VERSION ""

NS_ :

BS_:

BU_: Board Host

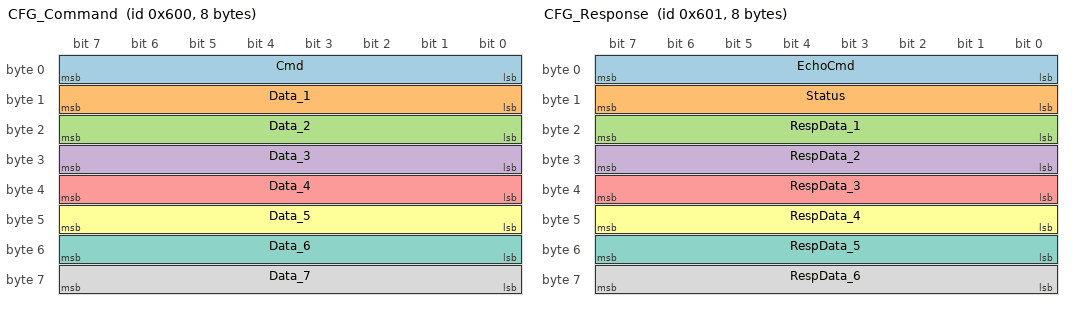
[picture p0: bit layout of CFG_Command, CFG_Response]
BO_ 1536 CFG_Command: 8 Host
 SG_ Cmd : 0|8@1+ (1,0) [0|33] "" Board
 SG_ Data_1 : 8|8@1+ (1,0) [0|255] "" Board
 SG_ Data_2 : 16|8@1+ (1,0) [0|255] "" Board
 SG_ Data_3 : 24|8@1+ (1,0) [0|255] "" Board
 SG_ Data_4 : 32|8@1+ (1,0) [0|255] "" Board
 SG_ Data_5 : 40|8@1+ (1,0) [0|255] "" Board
 SG_ Data_6 : 48|8@1+ (1,0) [0|255] "" Board
 SG_ Data_7 : 56|8@1+ (1,0) [0|255] "" Board

BO_ 1537 CFG_Response: 8 Board
 SG_ EchoCmd : 0|8@1+ (1,0) [0|33] "" Host
 SG_ Status : 8|8@1+ (1,0) [0|5] "" Host
 SG_ RespData_1 : 16|8@1+ (1,0) [0|255] "" Host
 SG_ RespData_2 : 24|8@1+ (1,0) [0|255] "" Host
 SG_ RespData_3 : 32|8@1+ (1,0) [0|255] "" Host
 SG_ RespData_4 : 40|8@1+ (1,0) [0|255] "" Host
 SG_ RespData_5 : 48|8@1+ (1,0) [0|255] "" Host
 SG_ RespData_6 : 56|8@1+ (1,0) [0|255] "" Host

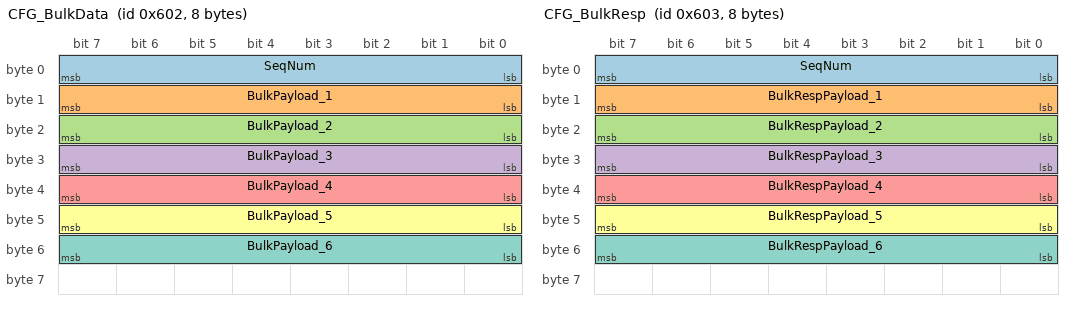
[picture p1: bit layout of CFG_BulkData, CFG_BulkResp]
BO_ 1538 CFG_BulkData: 8 Host
 SG_ SeqNum : 0|8@1+ (1,0) [0|255] "" Board
 SG_ BulkPayload_1 : 8|8@1+ (1,0) [0|255] "" Board
 SG_ BulkPayload_2 : 16|8@1+ (1,0) [0|255] "" Board
 SG_ BulkPayload_3 : 24|8@1+ (1,0) [0|255] "" Board
 SG_ BulkPayload_4 : 32|8@1+ (1,0) [0|255] "" Board
 SG_ BulkPayload_5 : 40|8@1+ (1,0) [0|255] "" Board
 SG_ BulkPayload_6 : 48|8@1+ (1,0) [0|255] "" Board

BO_ 1539 CFG_BulkResp: 8 Board
 SG_ SeqNum : 0|8@1+ (1,0) [0|255] "" Host
 SG_ BulkRespPayload_1 : 8|8@1+ (1,0) [0|255] "" Host
 SG_ BulkRespPayload_2 : 16|8@1+ (1,0) [0|255] "" Host
 SG_ BulkRespPayload_3 : 24|8@1+ (1,0) [0|255] "" Host
 SG_ BulkRespPayload_4 : 32|8@1+ (1,0) [0|255] "" Host
 SG_ BulkRespPayload_5 : 40|8@1+ (1,0) [0|255] "" Host
 SG_ BulkRespPayload_6 : 48|8@1+ (1,0) [0|255] "" Host

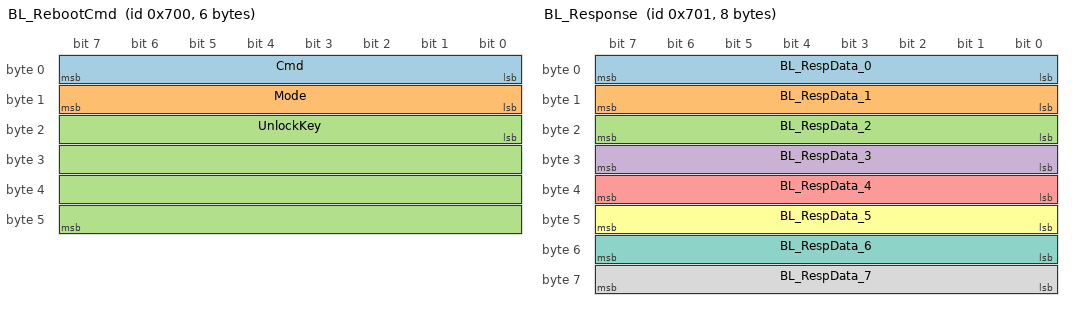
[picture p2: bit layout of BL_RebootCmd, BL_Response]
BO_ 1792 BL_RebootCmd: 6 Host
 SG_ Cmd : 0|8@1+ (1,0) [0|255] "" Board
 SG_ Mode : 8|8@1+ (1,0) [0|255] "" Board
 SG_ UnlockKey : 16|32@1+ (1,0) [0|0] "" Board

BO_ 1793 BL_Response: 8 Board
 SG_ BL_RespData_0 : 0|8@1+ (1,0) [0|255] "" Host
 SG_ BL_RespData_1 : 8|8@1+ (1,0) [0|255] "" Host
 SG_ BL_RespData_2 : 16|8@1+ (1,0) [0|255] "" Host
 SG_ BL_RespData_3 : 24|8@1+ (1,0) [0|255] "" Host
 SG_ BL_RespData_4 : 32|8@1+ (1,0) [0|255] "" Host
 SG_ BL_RespData_5 : 40|8@1+ (1,0) [0|255] "" Host
 SG_ BL_RespData_6 : 48|8@1+ (1,0) [0|255] "" Host
 SG_ BL_RespData_7 : 56|8@1+ (1,0) [0|255] "" Host

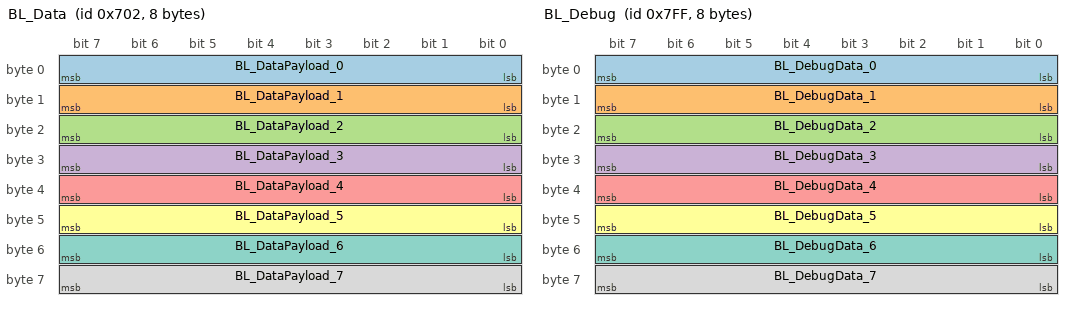
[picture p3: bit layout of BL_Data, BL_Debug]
BO_ 1794 BL_Data: 8 Host
 SG_ BL_DataPayload_0 : 0|8@1+ (1,0) [0|255] "" Board
 SG_ BL_DataPayload_1 : 8|8@1+ (1,0) [0|255] "" Board
 SG_ BL_DataPayload_2 : 16|8@1+ (1,0) [0|255] "" Board
 SG_ BL_DataPayload_3 : 24|8@1+ (1,0) [0|255] "" Board
 SG_ BL_DataPayload_4 : 32|8@1+ (1,0) [0|255] "" Board
 SG_ BL_DataPayload_5 : 40|8@1+ (1,0) [0|255] "" Board
 SG_ BL_DataPayload_6 : 48|8@1+ (1,0) [0|255] "" Board
 SG_ BL_DataPayload_7 : 56|8@1+ (1,0) [0|255] "" Board

BO_ 2047 BL_Debug: 8 Board
 SG_ BL_DebugData_0 : 0|8@1+ (1,0) [0|255] "" Host
 SG_ BL_DebugData_1 : 8|8@1+ (1,0) [0|255] "" Host
 SG_ BL_DebugData_2 : 16|8@1+ (1,0) [0|255] "" Host
 SG_ BL_DebugData_3 : 24|8@1+ (1,0) [0|255] "" Host
 SG_ BL_DebugData_4 : 32|8@1+ (1,0) [0|255] "" Host
 SG_ BL_DebugData_5 : 40|8@1+ (1,0) [0|255] "" Host
 SG_ BL_DebugData_6 : 48|8@1+ (1,0) [0|255] "" Host
 SG_ BL_DebugData_7 : 56|8@1+ (1,0) [0|255] "" Host

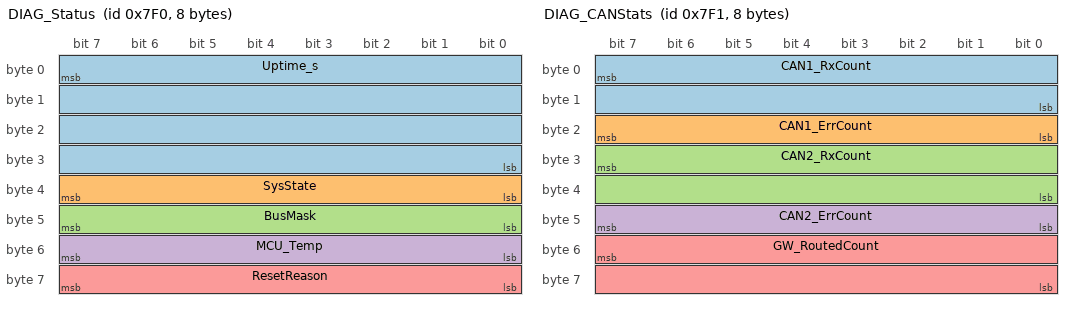
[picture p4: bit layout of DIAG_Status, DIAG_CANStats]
BO_ 2032 DIAG_Status: 8 Board
 SG_ Uptime_s : 7|32@0+ (1,0) [0|0] "s" Host
 SG_ SysState : 32|8@1+ (1,0) [0|3] "" Host
 SG_ BusMask : 40|8@1+ (1,0) [0|63] "" Host
 SG_ MCU_Temp : 48|8@1- (1,0) [-40|125] "degC" Host
 SG_ ResetReason : 56|8@1+ (1,0) [0|3] "" Host

BO_ 2033 DIAG_CANStats: 8 Board
 SG_ CAN1_RxCount : 7|16@0+ (1,0) [0|65535] "" Host
 SG_ CAN1_ErrCount : 16|8@1+ (1,0) [0|255] "" Host
 SG_ CAN2_RxCount : 31|16@0+ (1,0) [0|65535] "" Host
 SG_ CAN2_ErrCount : 40|8@1+ (1,0) [0|255] "" Host
 SG_ GW_RoutedCount : 55|16@0+ (1,0) [0|65535] "" Host

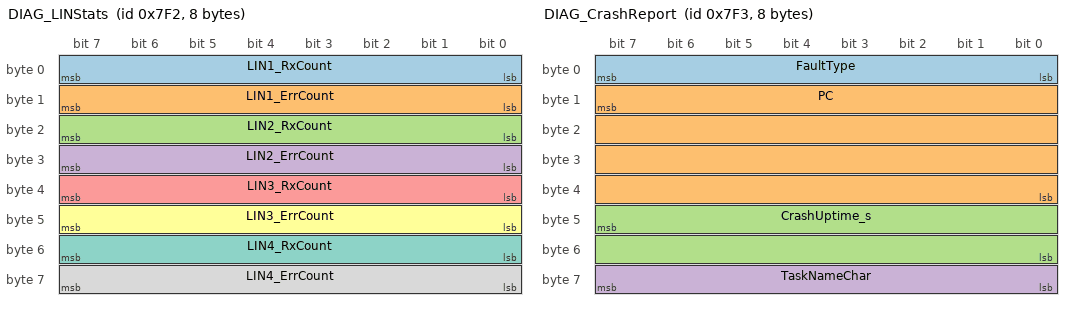
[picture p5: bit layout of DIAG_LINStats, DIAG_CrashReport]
BO_ 2034 DIAG_LINStats: 8 Board
 SG_ LIN1_RxCount : 0|8@1+ (1,0) [0|255] "" Host
 SG_ LIN1_ErrCount : 8|8@1+ (1,0) [0|255] "" Host
 SG_ LIN2_RxCount : 16|8@1+ (1,0) [0|255] "" Host
 SG_ LIN2_ErrCount : 24|8@1+ (1,0) [0|255] "" Host
 SG_ LIN3_RxCount : 32|8@1+ (1,0) [0|255] "" Host
 SG_ LIN3_ErrCount : 40|8@1+ (1,0) [0|255] "" Host
 SG_ LIN4_RxCount : 48|8@1+ (1,0) [0|255] "" Host
 SG_ LIN4_ErrCount : 56|8@1+ (1,0) [0|255] "" Host

BO_ 2035 DIAG_CrashReport: 8 Board
 SG_ FaultType : 0|8@1+ (1,0) [0|5] "" Host
 SG_ PC : 15|32@0+ (1,0) [0|0] "" Host
 SG_ CrashUptime_s : 47|16@0+ (1,0) [0|65535] "s" Host
 SG_ TaskNameChar : 56|8@1+ (1,0) [0|255] "" Host

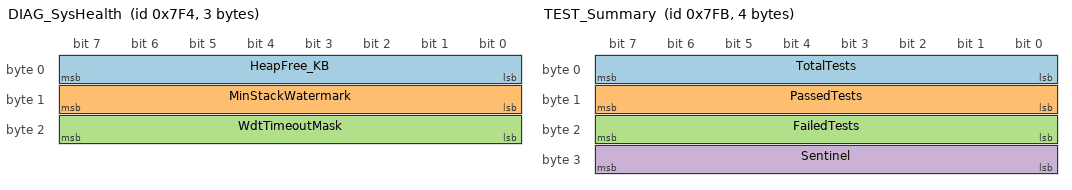
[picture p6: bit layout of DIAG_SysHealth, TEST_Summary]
BO_ 2036 DIAG_SysHealth: 3 Board
 SG_ HeapFree_KB : 0|8@1+ (1,0) [0|255] "KB" Host
 SG_ MinStackWatermark : 8|8@1+ (1,0) [0|255] "words" Host
 SG_ WdtTimeoutMask : 16|8@1+ (1,0) [0|63] "" Host

BO_ 2042 TEST_Result: 8 Board
 SG_ TestID : 0|8@1+ (1,0) [0|255] "" Host
 SG_ Result : 8|8@1+ (1,0) [0|2] "" Host

BO_ 2043 TEST_Summary: 4 Board
 SG_ TotalTests : 0|8@1+ (1,0) [0|255] "" Host
 SG_ PassedTests : 8|8@1+ (1,0) [0|255] "" Host
 SG_ FailedTests : 16|8@1+ (1,0) [0|255] "" Host
 SG_ Sentinel : 24|8@1+ (1,0) [0|255] "" Host

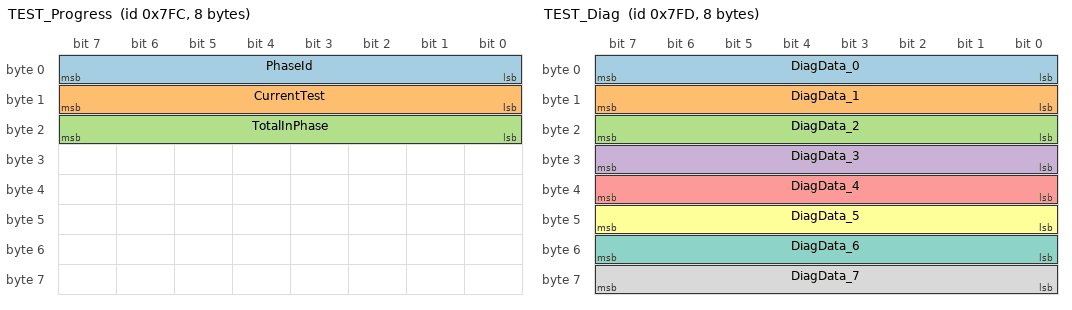
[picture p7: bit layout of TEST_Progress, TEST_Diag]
BO_ 2044 TEST_Progress: 8 Board
 SG_ PhaseId : 0|8@1+ (1,0) [0|255] "" Host
 SG_ CurrentTest : 8|8@1+ (1,0) [0|255] "" Host
 SG_ TotalInPhase : 16|8@1+ (1,0) [0|255] "" Host

BO_ 2045 TEST_Diag: 8 Board
 SG_ DiagData_0 : 0|8@1+ (1,0) [0|255] "" Host
 SG_ DiagData_1 : 8|8@1+ (1,0) [0|255] "" Host
 SG_ DiagData_2 : 16|8@1+ (1,0) [0|255] "" Host
 SG_ DiagData_3 : 24|8@1+ (1,0) [0|255] "" Host
 SG_ DiagData_4 : 32|8@1+ (1,0) [0|255] "" Host
 SG_ DiagData_5 : 40|8@1+ (1,0) [0|255] "" Host
 SG_ DiagData_6 : 48|8@1+ (1,0) [0|255] "" Host
 SG_ DiagData_7 : 56|8@1+ (1,0) [0|255] "" Host

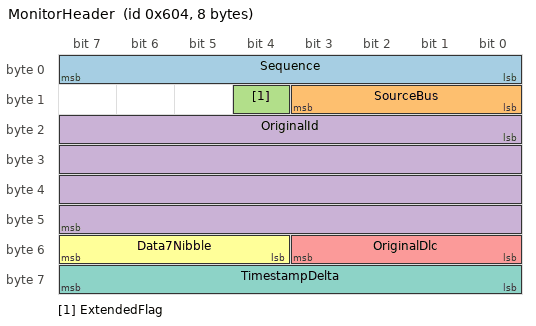
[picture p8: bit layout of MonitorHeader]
BO_ 1540 MonitorHeader: 8 Gateway
 SG_ Sequence : 0|8@1+ (1,0) [0|255] "" Tool
 SG_ SourceBus : 8|4@1+ (1,0) [0|5] "" Tool
 SG_ ExtendedFlag : 12|1@1+ (1,0) [0|1] "" Tool
 SG_ OriginalId : 16|32@1+ (1,0) [0|536870911] "" Tool
 SG_ OriginalDlc : 48|4@1+ (1,0) [0|8] "" Tool
 SG_ Data7Nibble : 52|4@1+ (1,0) [0|15] "" Tool
 SG_ TimestampDelta : 56|8@1+ (1,0) [0|255] "ms" Tool

BO_ 1541 MonitorData: 8 Gateway
 SG_ Sequence : 0|8@1+ (1,0) [0|255] "" Tool
 SG_ Payload : 8|56@1+ (1,0) [0|0] "" Tool

CM_ BU_ Board "CAN/LIN gateway board (RP2350, FreeRTOS). CAN1 always on, CAN2 switchable.";
CM_ BU_ Host "External host tool (Windows config app or PCAN test script).";

CM_ BO_ 1536 "Config command from host. Byte 0 = command code; remaining bytes are command-specific. See config_protocol.h for full details.\n\nCmd values:\n  0x01 CONNECT - no payload, returns FW version\n  0x02 SAVE - save working config to NVM\n  0x03 DEFAULTS - reset config to factory defaults\n  0x04 REBOOT - MCU software reset\n  0x05 ENTER_BL - bytes 1-4: unlock key 0xB007CAFE (LE)\n  0x06 GET_STATUS - returns NVM write count\n  0x10 READ_PARAM - bytes 1-3: section/param/sub\n  0x11 WRITE_PARAM - bytes 1-3: section/param/sub, bytes 4+: value (LE)\n  0x20 BULK_START - byte 1: section, byte 2: sub, bytes 3-4: size (LE), bytes 5-7: CRC24 (LE, lower 24 bits of CRC32)\n  0x21 BULK_END - finalize bulk transfer\n  0x22 BULK_READ - byte 1: section (0x02=routing, 0x01=LIN), byte 2: sub (LIN channel). Response on 0x601 with size+CRC (no data yet)\n  0x23 BULK_READ_DATA - no payload; triggers data stream on 0x603. Must follow a successful BULK_READ";

CM_ BO_ 1537 "Config response from board. Byte 0 echoes the command; byte 1 = status code; bytes 2+ are command-specific payload.\n\nCONNECT response (DLC=8): bytes 2-4: FW major/minor/patch, bytes 5-6: sizeof(nvm_config_t) LE, byte 7: routing rule count.\nGET_STATUS response (DLC=6): bytes 2-5: NVM write count (LE).\nREAD_PARAM response: bytes 2-4: section/param/sub echo, bytes 5+: value (LE).";

CM_ BO_ 1538 "Bulk data frames during bulk write transfer (host to board). Byte 0 = sequence number (0,1,2,...). Bytes 1-7 = payload (up to 7 bytes per frame). No individual ACK per frame; send BULK_END (0x21) to finalize.";

CM_ BO_ 1539 "Bulk data response frames during bulk read transfer (board to host). Sent after a BULK_READ_DATA (0x23) ACK. Byte 0 = sequence number (0,1,2,...). Bytes 1-7 = payload (up to 7 bytes per frame). Host reads total size and CRC from the preceding BULK_READ (0x22) response.";

CM_ BO_ 1792 "Bootloader reboot trigger handled by application firmware. Cmd must be 0x05 (CMD_RESET), Mode must be 0x01 (RESET_MODE_BOOTLOADER). UnlockKey = 0xB007CAFE (little-endian). Board writes SRAM magic and reboots immediately (no response sent). Other 0x700 commands are handled by the bootloader only.";

CM_ BO_ 1793 "Bootloader command response and heartbeat. Used by the bootloader (not application firmware). In bootloader mode: byte 0 echoes the command, byte 1 = status. In idle: periodic heartbeat (1 Hz). See bootloader documentation for signal layout.";

CM_ BO_ 1794 "Bootloader firmware data frames. Used during CAN flash programming (host sends firmware chunks to the board). Payload layout depends on the active bootloader command. See bootloader documentation.";

CM_ BO_ 2047 "Bootloader debug output. Free-form diagnostic data emitted by the bootloader during flash operations or error conditions. Not used by application firmware. See bootloader documentation.";

CM_ BO_ 2032 "Diagnostic heartbeat, sent every 1 second (configurable) on configured CAN bus.\n\nNote: At boot, a one-shot version frame is sent ONCE on this same CAN ID with a DIFFERENT layout (DLC=6):\n  bytes 0-2: FW version major/minor/patch\n  byte 3: 0xAA sentinel (distinguishes from periodic heartbeat)\n  bytes 4-5: app CRC32 bits [15:0] (big-endian)\nThe periodic heartbeat (DLC=8) starts after the version frame.";

CM_ BO_ 2033 "CAN bus and gateway statistics, sent every 1 second (5 ms after DIAG_Status). All counters are lower 16 or 8 bits, wrapping.";

CM_ BO_ 2034 "LIN channel statistics for all 4 channels, sent every 1 second (10 ms after DIAG_Status). 2 bytes per channel: RX count (saturated at 255) and error count (saturated at 255).";

CM_ BO_ 2035 "Crash report, sent once at boot if a valid crash record exists in watchdog scratch registers. Cleared after transmission. Only present if the previous boot ended in a fault.";

CM_ BO_ 2036 "System health indicators, sent every 1 second (15 ms after DIAG_Status). Heap, stack watermark, and bus watchdog timeout monitoring.";

CM_ BO_ 2042 "Test result frame (test firmware only). Sent once per test case. TestID = test number within the phase. Result: 0=PASS, 1=FAIL, 2=SKIP. Bytes 2-7 may carry test-specific auxiliary data.";

CM_ BO_ 2043 "Test summary frame (test firmware only). Sent once at end of a test run. Sentinel is always 0xAA.";
CM_ BO_ 2044 "Test progress frame (test firmware only). Indicates which test is currently running within a phase.";
CM_ BO_ 2045 "Test diagnostic frame (test firmware only). Carries auxiliary debug data during tests (crash PC/LR, measured values, etc.).";

CM_ SG_ 1536 Cmd "Config command code. See config_protocol.h for values.";
CM_ SG_ 1537 EchoCmd "Echo of the command code that generated this response.";
CM_ SG_ 1537 Status "Response status: 0=OK, 1=UnknownCmd, 2=InvalidParam, 3=CRCMismatch, 4=NVMError, 5=Busy.";
CM_ SG_ 1538 SeqNum "Sequence counter starting at 0, incrementing per bulk data frame. Sequence error aborts the transfer.";
CM_ SG_ 1792 Cmd "Must be 0x05 (CMD_RESET).";
CM_ SG_ 1792 Mode "Must be 0x01 (RESET_MODE_BOOTLOADER).";
CM_ SG_ 1792 UnlockKey "Reset unlock key = 0xB007CAFE (little-endian).";
CM_ SG_ 2032 Uptime_s "Seconds since boot (32-bit, big-endian).";
CM_ SG_ 2032 SysState "System state enum: 0=BOOT, 1=OK, 2=WARN, 3=ERROR.";
CM_ SG_ 2032 BusMask "Active bus bitmask: bit0=CAN1, bit1=CAN2, bit2=LIN1, bit3=LIN2, bit4=LIN3, bit5=LIN4.";
CM_ SG_ 2032 MCU_Temp "RP2350 die temperature (signed). Formula: T = 27 - (V - 0.706) / 0.001721.";
CM_ SG_ 2032 ResetReason "Reset reason enum: 0=PowerOn, 1=WatchdogTimeout, 2=CrashReboot, 3=Unknown.";
CM_ SG_ 2033 CAN1_RxCount "CAN1 received frame count (lower 16 bits, wrapping).";
CM_ SG_ 2033 CAN1_ErrCount "CAN1 error count (saturated at 255).";
CM_ SG_ 2033 CAN2_RxCount "CAN2 received frame count (lower 16 bits, wrapping).";
CM_ SG_ 2033 CAN2_ErrCount "CAN2 error count (saturated at 255).";
CM_ SG_ 2033 GW_RoutedCount "Gateway routed frame count (lower 16 bits, wrapping).";
CM_ SG_ 2034 LIN1_RxCount "LIN channel 1 RX frame count (saturated at 255).";
CM_ SG_ 2034 LIN1_ErrCount "LIN channel 1 error count (saturated at 255).";
CM_ SG_ 2034 LIN2_RxCount "LIN channel 2 RX frame count (saturated at 255).";
CM_ SG_ 2034 LIN2_ErrCount "LIN channel 2 error count (saturated at 255).";
CM_ SG_ 2034 LIN3_RxCount "LIN channel 3 RX frame count (saturated at 255).";
CM_ SG_ 2034 LIN3_ErrCount "LIN channel 3 error count (saturated at 255).";
CM_ SG_ 2034 LIN4_RxCount "LIN channel 4 RX frame count (saturated at 255).";
CM_ SG_ 2034 LIN4_ErrCount "LIN channel 4 error count (saturated at 255).";
CM_ SG_ 2035 FaultType "Fault type enum: 0=None, 1=HardFault, 2=StackOverflow, 3=MallocFail, 4=AssertFail, 5=WatchdogTimeout.";
CM_ SG_ 2035 PC "Program counter at fault location (32-bit, big-endian). Thumb addresses have bit 0 set.";
CM_ SG_ 2035 CrashUptime_s "Uptime in seconds when the crash occurred (big-endian, 16-bit).";
CM_ SG_ 2035 TaskNameChar "First ASCII character of the faulting FreeRTOS task name.";
CM_ SG_ 2036 HeapFree_KB "Free FreeRTOS heap in kilobytes.";
CM_ SG_ 2036 MinStackWatermark "Minimum stack high-water mark across all tasks (in words, saturated at 255).";
CM_ SG_ 2036 WdtTimeoutMask "Bus software watchdog timeout bitmask: bit0=CAN1, bit1=CAN2, bit2=LIN1, bit3=LIN2, bit4=LIN3, bit5=LIN4. 0=no timeout.";

BA_DEF_ BO_ "GenMsgCycleTime" INT 0 10000;
BA_DEF_ BO_ "GenMsgSendType" STRING;

BA_DEF_DEF_ "GenMsgCycleTime" 0;
BA_DEF_DEF_ "GenMsgSendType" "";

BA_ "GenMsgSendType" BO_ 1536 "NoMsgSendType";
BA_ "GenMsgSendType" BO_ 1537 "NoMsgSendType";
BA_ "GenMsgSendType" BO_ 1538 "NoMsgSendType";
BA_ "GenMsgSendType" BO_ 1539 "NoMsgSendType";
BA_ "GenMsgSendType" BO_ 1792 "NoMsgSendType";
BA_ "GenMsgSendType" BO_ 1793 "NoMsgSendType";
BA_ "GenMsgSendType" BO_ 1794 "NoMsgSendType";
BA_ "GenMsgSendType" BO_ 2047 "NoMsgSendType";
BA_ "GenMsgSendType" BO_ 2032 "Cyclic";
BA_ "GenMsgCycleTime" BO_ 2032 1000;
BA_ "GenMsgSendType" BO_ 2033 "Cyclic";
BA_ "GenMsgCycleTime" BO_ 2033 1000;
BA_ "GenMsgSendType" BO_ 2034 "Cyclic";
BA_ "GenMsgCycleTime" BO_ 2034 1000;
BA_ "GenMsgSendType" BO_ 2035 "Event";
BA_ "GenMsgSendType" BO_ 2036 "Cyclic";
BA_ "GenMsgCycleTime" BO_ 2036 1000;
BA_ "GenMsgSendType" BO_ 2042 "Event";
BA_ "GenMsgSendType" BO_ 2043 "Event";
BA_ "GenMsgSendType" BO_ 2044 "Event";
BA_ "GenMsgSendType" BO_ 2045 "Event";

VAL_ 1537 Status 0 "OK" 1 "UnknownCmd" 2 "InvalidParam" 3 "CRCMismatch" 4 "NVMError" 5 "Busy" ;
VAL_ 2032 SysState 0 "BOOT" 1 "OK" 2 "WARN" 3 "ERROR" ;
VAL_ 2032 ResetReason 0 "PowerOn" 1 "WatchdogTimeout" 2 "CrashReboot" 3 "Unknown" ;
VAL_ 2035 FaultType 0 "None" 1 "HardFault" 2 "StackOverflow" 3 "MallocFail" 4 "AssertFail" 5 "WatchdogTimeout" ;
VAL_ 2042 Result 0 "PASS" 1 "FAIL" 2 "SKIP" ;
VAL_ 1536 Cmd 1 "CONNECT" 2 "SAVE" 3 "DEFAULTS" 4 "REBOOT" 5 "ENTER_BL" 6 "GET_STATUS" 16 "READ_PARAM" 17 "WRITE_PARAM" 32 "BULK_START" 33 "BULK_END" 34 "BULK_READ" 35 "BULK_READ_DATA" ;
